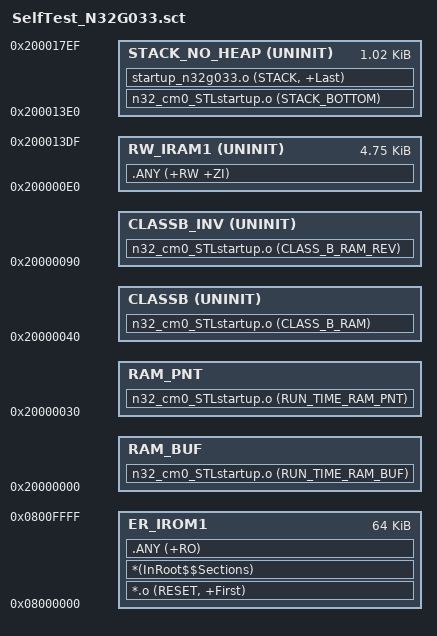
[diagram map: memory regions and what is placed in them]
; ****************************************************************
; Scatter-Loading Description File for IEC 60335 compliant project
; ****************************************************************
; WARNING: Class B variables and their inverse redundant parts
; must be manually placed using the __at attributes in the 
; n32g45x_SelfTest_classBvar.h file.
; The start address of CLASSB, CLASSB_INV and RW_IRAM1 region 
; must be manually modified to be in-line with this file.

  LR_IROM1 0x08000000 0x00010000  {    ; load region size_region
    ER_IROM1 0x08000000 0x00010000  {  ; load address = execution address
      *.o (RESET, +First)
      *(InRoot$$Sections)
      .ANY (+RO)
    }
	
    RAM_BUF 0x20000000 
    {			; Run-time transparent RAM test buffer
      n32_cm0_STLstartup.o (RUN_TIME_RAM_BUF)
    }

    RAM_PNT 0x20000030	
    {			; Run-time transparent RAM test pointer
      n32_cm0_STLstartup.o (RUN_TIME_RAM_PNT)
    }

    CLASSB 0x20000040 UNINIT
    {		        ; Class B variables
    n32_cm0_STLstartup.o (CLASS_B_RAM)
    }

    CLASSB_INV 0x20000090 UNINIT 
    {              ; Class B inverted variables
    n32_cm0_STLstartup.o (CLASS_B_RAM_REV)
    }

    RW_IRAM1 0x200000E0 UNINIT 0x00001300
    {     ; RW data (Class A variables)
      .ANY (+RW +ZI)
    }
    
    STACK_NO_HEAP 0x200013E0 UNINIT 0x410  { ; Stack and magic pattern for stack overflow detection
   	  n32_cm0_STLstartup.o (STACK_BOTTOM)
	  startup_n32g033.o (STACK, +Last) ;select right startup file
    }
	
  }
